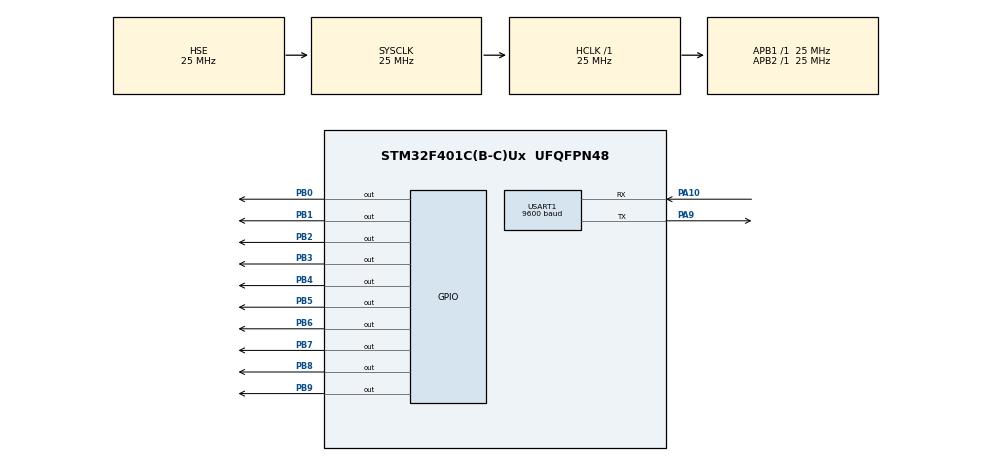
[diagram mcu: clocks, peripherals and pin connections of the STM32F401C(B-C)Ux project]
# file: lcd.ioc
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Mcu.Family=STM32F4
Mcu.Name=STM32F401C(B-C)Ux
Mcu.Package=UFQFPN48
NVIC.PriorityGroup=NVIC_PRIORITYGROUP_4
NVIC.USART1_IRQn=true\:0\:0\:false\:false\:true\:true\:true\:true
PA10.Mode=Asynchronous
PA10.Signal=USART1_RX
PA9.Mode=Asynchronous
PA9.Signal=USART1_TX
PB0.Signal=GPIO_Output
PB1.Signal=GPIO_Output
PB2.Signal=GPIO_Output
PB3.Signal=GPIO_Output
PB4.Signal=GPIO_Output
PB5.Signal=GPIO_Output
PB6.Signal=GPIO_Output
PB7.Signal=GPIO_Output
PB8.Signal=GPIO_Output
PB9.Signal=GPIO_Output
PH0\ -\ OSC_IN.Mode=HSE-External-Oscillator
PH0\ -\ OSC_IN.Signal=RCC_OSC_IN
PH1\ -\ OSC_OUT.Mode=HSE-External-Oscillator
PH1\ -\ OSC_OUT.Signal=RCC_OSC_OUT
ProjectManager.HeapSize=0x200
ProjectManager.StackSize=0x400
ProjectManager.TargetToolchain=STM32CubeIDE
RCC.48MHZClocksFreq_Value=75000000
RCC.AHBFreq_Value=25000000
RCC.APB1Freq_Value=25000000
RCC.APB1TimFreq_Value=25000000
RCC.APB2Freq_Value=25000000
RCC.APB2TimFreq_Value=25000000
RCC.CortexFreq_Value=25000000
RCC.HCLKFreq_Value=25000000
RCC.HSE_VALUE=25000000
RCC.HSI_VALUE=16000000
RCC.LSE_VALUE=32768
RCC.PLLSourceVirtual=RCC_PLLSOURCE_HSE
RCC.SYSCLKFreq_VALUE=25000000
RCC.SYSCLKSource=RCC_SYSCLKSOURCE_HSE
RCC.VCOOutputFreq_Value=300000000
USART1.BaudRate=9600
USART1.VirtualMode=VM_ASYNC
board=custom

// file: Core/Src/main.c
/* USER CODE BEGIN Header */
/**
  ******************************************************************************
  * @file           : main.c
  * @brief          : Main program body
  ******************************************************************************
  * @attention
  *
  * Copyright (c) 2022 STMicroelectronics.
  * All rights reserved.
  *
  * This software is licensed under terms that can be found in the LICENSE file
  * in the root directory of this software component.
  * If no LICENSE file comes with this software, it is provided AS-IS.
  *
  ******************************************************************************
  */
/* USER CODE END Header */
#include <stdio.h>
#include <stdlib.h>
#include <string.h>
#include "main.h"
#include "lcd.h"
#include "linked_list.h"
#include "nmea.h"

/* USER CODE BEGIN PD */
#define BUFFSIZE (500)
/* USER CODE END PD */

 UART_HandleTypeDef huart1;

void SystemClock_Config(void);
static void MX_GPIO_Init(void);
static void MX_USART1_UART_Init(void);

char uart_buffer[BUFFSIZE] = {0};

int main(void)
{

  /* MCU Configuration--------------------------------------------------------*/

  /* Reset of all peripherals, Initializes the Flash interface and the Systick. */
  HAL_Init();

  /* Configure the system clock */
  SystemClock_Config();

  /* Initialize all configured peripherals */
  MX_GPIO_Init();
  MX_USART1_UART_Init();

  /* Infinite loop */
  /* USER CODE BEGIN WHILE */
  init();

//  lcd_print("1234567890abcdefghjgABCDEFGHJ1234567890abcdefgh", 0, 0);
  rmc_t rmc = {0};
  gsv_t gsv = {0};
  gga_t gga = {0};

//  parse_nmea(example, &data);

  lcd_printf(0, 0, "Starting ...");
  while (1)
  {
    /* USER CODE END WHILE */
//	  HAL_UART_Receive_IT(&huart1, buffer, BUFFSIZE);
	  HAL_UART_Receive(&huart1, (uint8_t *)uart_buffer, BUFFSIZE, 230);
	  if (parse_nmea(uart_buffer, &rmc, &gsv, &gga) != RC_OK)
	  {
		  continue;
	  }

	  lcd_printf(0, 0, "%02d:%02d:%02d F %d S %02d.%02d", rmc.time.hour, rmc.time.minute, rmc.time.second, gga.pos_fix, rmc.speed.high, rmc.speed.low);
	  lcd_printf(1, 0, "%02d%c%02d.%05d Sats %02d", rmc.latitude.degree, 0xdf, rmc.latitude.minute, rmc.latitude.seconds, gsv.satelites_num);
	  lcd_printf(2, 0, "%02d%c%02d.%05d Used %02d", rmc.longitude.degree, 0xdf, rmc.longitude.minute, rmc.longitude.seconds, gga.sats_used);
	  lcd_printf(3, 0, "H %02d.%02d A %02d.%02d", gga.hdop.high, gga.hdop.low, gga.altitude.high, gga.altitude.low);

  }
}

void HAL_UART_RxCpltCallback(UART_HandleTypeDef *huart)
{
	__NOP();
}

void SystemClock_Config(void)
{
  RCC_OscInitTypeDef RCC_OscInitStruct = {0};
  RCC_ClkInitTypeDef RCC_ClkInitStruct = {0};

  /** Configure the main internal regulator output voltage
  */
  __HAL_RCC_PWR_CLK_ENABLE();
  __HAL_PWR_VOLTAGESCALING_CONFIG(PWR_REGULATOR_VOLTAGE_SCALE2);

  /** Initializes the RCC Oscillators according to the specified parameters
  * in the RCC_OscInitTypeDef structure.
  */
  RCC_OscInitStruct.OscillatorType = RCC_OSCILLATORTYPE_HSE;
  RCC_OscInitStruct.HSEState = RCC_HSE_ON;
  RCC_OscInitStruct.PLL.PLLState = RCC_PLL_NONE;
  if (HAL_RCC_OscConfig(&RCC_OscInitStruct) != HAL_OK)
  {
    Error_Handler();
  }

  /** Initializes the CPU, AHB and APB buses clocks
  */
  RCC_ClkInitStruct.ClockType = RCC_CLOCKTYPE_HCLK|RCC_CLOCKTYPE_SYSCLK
                              |RCC_CLOCKTYPE_PCLK1|RCC_CLOCKTYPE_PCLK2;
  RCC_ClkInitStruct.SYSCLKSource = RCC_SYSCLKSOURCE_HSE;
  RCC_ClkInitStruct.AHBCLKDivider = RCC_SYSCLK_DIV1;
  RCC_ClkInitStruct.APB1CLKDivider = RCC_HCLK_DIV1;
  RCC_ClkInitStruct.APB2CLKDivider = RCC_HCLK_DIV1;

  if (HAL_RCC_ClockConfig(&RCC_ClkInitStruct, FLASH_LATENCY_0) != HAL_OK)
  {
    Error_Handler();
  }
}

static void MX_USART1_UART_Init(void)
{

  huart1.Instance = USART1;
  huart1.Init.BaudRate = 9600;
  huart1.Init.WordLength = UART_WORDLENGTH_8B;
  huart1.Init.StopBits = UART_STOPBITS_1;
  huart1.Init.Parity = UART_PARITY_NONE;
  huart1.Init.Mode = UART_MODE_TX_RX;
  huart1.Init.HwFlowCtl = UART_HWCONTROL_NONE;
  huart1.Init.OverSampling = UART_OVERSAMPLING_16;
  if (HAL_UART_Init(&huart1) != HAL_OK)
  {
    Error_Handler();
  }

}

static void MX_GPIO_Init(void)
{
  GPIO_InitTypeDef GPIO_InitStruct = {0};

  /* GPIO Ports Clock Enable */
  __HAL_RCC_GPIOH_CLK_ENABLE();
  __HAL_RCC_GPIOB_CLK_ENABLE();
  __HAL_RCC_GPIOA_CLK_ENABLE();

  /*Configure GPIO pin Output Level */
  HAL_GPIO_WritePin(GPIOB, GPIO_PIN_0|GPIO_PIN_1|GPIO_PIN_2|GPIO_PIN_3
                          |GPIO_PIN_4|GPIO_PIN_5|GPIO_PIN_6|GPIO_PIN_7
                          |GPIO_PIN_8|GPIO_PIN_9, GPIO_PIN_RESET);

  /*Configure GPIO pins : PB0 PB1 PB2 PB3
                           PB4 PB5 PB6 PB7
                           PB8 PB9 */
  GPIO_InitStruct.Pin = GPIO_PIN_0|GPIO_PIN_1|GPIO_PIN_2|GPIO_PIN_3
                          |GPIO_PIN_4|GPIO_PIN_5|GPIO_PIN_6|GPIO_PIN_7
                          |GPIO_PIN_8|GPIO_PIN_9;
  GPIO_InitStruct.Mode = GPIO_MODE_OUTPUT_PP;
  GPIO_InitStruct.Pull = GPIO_NOPULL;
  GPIO_InitStruct.Speed = GPIO_SPEED_FREQ_LOW;
  HAL_GPIO_Init(GPIOB, &GPIO_InitStruct);

}

void Error_Handler(void)
{
  __disable_irq();
  while (1)
  {
  }
}
